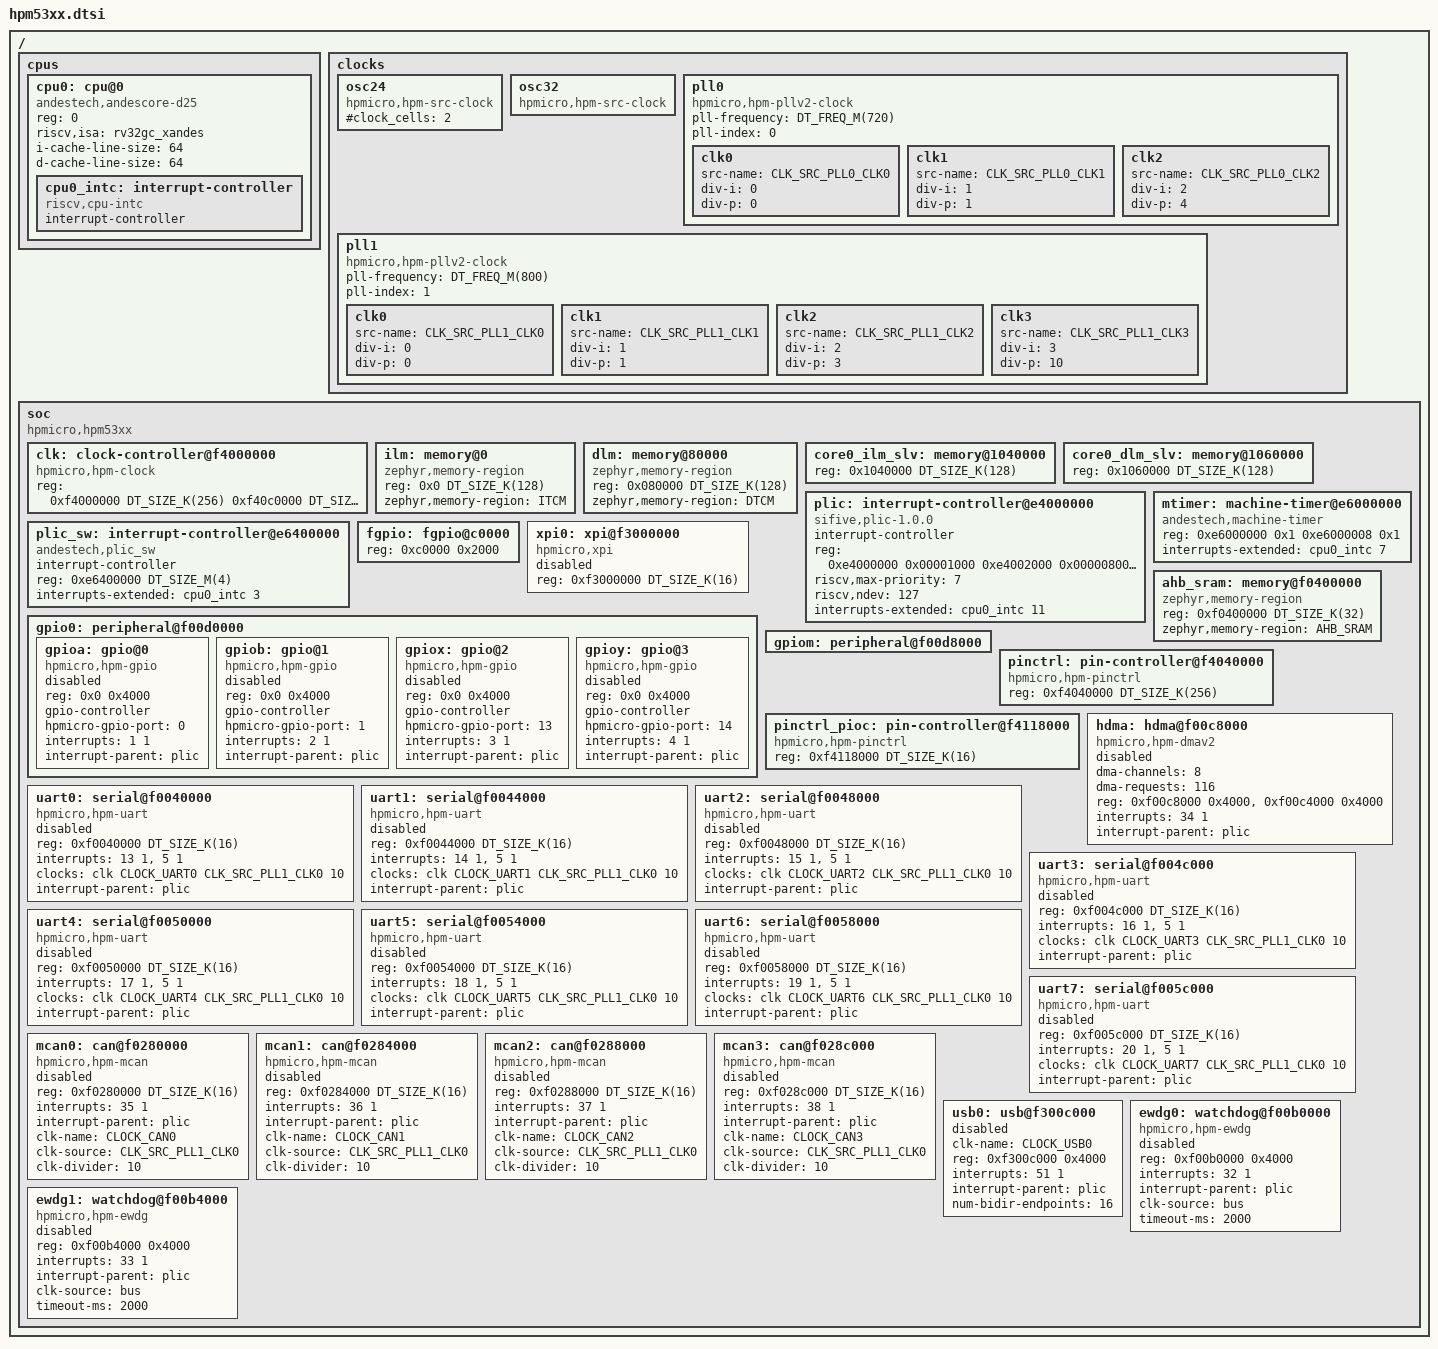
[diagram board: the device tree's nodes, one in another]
/*
 * Copyright 2024 HPMicro
 * SPDX-License-Identifier: Apache-2.0
 */

/dts-v1/;
#include <zephyr/dt-bindings/gpio/gpio.h>
#include <zephyr/dt-bindings/i2c/i2c.h>
#include <dt-bindings/clock/hpm5361-clocks.h>
#include <mem.h>
#include <freq.h>

/ {
	#address-cells = <1>;
	#size-cells = <1>;

	cpus {
		#address-cells = <1>;
		#size-cells = <0>;
		cpu0: cpu@0 {
			compatible = "andestech,andescore-d25", "riscv"; /* riscv custom */
			reg = <0>;
			status = "okay";
			riscv,isa = "rv32gc_xandes";
			i-cache-line-size = <64>;
			d-cache-line-size = <64>;

			cpu0_intc: interrupt-controller {
				compatible = "riscv,cpu-intc";
				#address-cells = <0>;
				#interrupt-cells = <1>;
				interrupt-controller;
			};
		};
	};

    clocks {
        osc24: osc24 {
            #clock_cells = <2>;
            compatible = "hpmicro,hpm-src-clock";
        };

		osc32: osc32 {
			#clock-cells = <2>;
			compatible = "hpmicro,hpm-src-clock";
		};

		pll0: pll0 {
			#clock-cells = <2>;
			compatible = "hpmicro,hpm-pllv2-clock";
			pll-frequency = <DT_FREQ_M(720)>;
			pll-index = <0>;

			clk0 {
				src-name = <CLK_SRC_PLL0_CLK0>;
				div-i = <0>;
				div-p = <0>;
			};

			clk1 {
				src-name = <CLK_SRC_PLL0_CLK1>;
				div-i = <1>;
				div-p = <1>;
			};

			clk2 {
				src-name = <CLK_SRC_PLL0_CLK2>;
				div-i = <2>;
				div-p = <4>;
			};
		};

		pll1: pll1 {
			#clock-cells = <2>;
			compatible = "hpmicro,hpm-pllv2-clock";
			pll-frequency = <DT_FREQ_M(800)>;
			pll-index = <1>;

			clk0 {
				src-name = <CLK_SRC_PLL1_CLK0>;
				div-i = <0>;
				div-p = <0>;
			};

			clk1 {
				src-name = <CLK_SRC_PLL1_CLK1>;
				div-i = <1>;
				div-p = <1>;
			};

			clk2 {
				src-name = <CLK_SRC_PLL1_CLK2>;
				div-i = <2>;
				div-p = <3>;
			};

			clk3 {
				src-name = <CLK_SRC_PLL1_CLK3>;
				div-i = <3>;
				div-p = <10>;
			};
		};
    };

    soc {
		#address-cells = <1>;
		#size-cells = <1>;
		compatible = "hpmicro,hpm53xx";
		ranges;

        clk: clock-controller@f4000000 {
            compatible = "hpmicro,hpm-clock";
            reg = <0xf4000000 DT_SIZE_K(256)
                0xf40c0000 DT_SIZE_K(256)>;
            reg-names = "sysctl", "pll";
            #clock-cells = <3>;
            status = "okay";
        };

		ilm: memory@0 {
			compatible = "zephyr,memory-region";
			reg = <0x0 DT_SIZE_K(128)>;
			zephyr,memory-region = "ITCM";
		};

		dlm: memory@80000 {
			compatible = "zephyr,memory-region";
			reg = <0x080000 DT_SIZE_K(128)>;
			zephyr,memory-region = "DTCM";
		};

		core0_ilm_slv: memory@1040000 {
			reg = <0x1040000 DT_SIZE_K(128)>;
		};

		core0_dlm_slv: memory@1060000 {
			reg = <0x1060000 DT_SIZE_K(128)>;
		};

		plic: interrupt-controller@e4000000 {
			compatible = "sifive,plic-1.0.0";
			#address-cells = <1>;
			#interrupt-cells = <2>;
			interrupt-controller;
			reg = <	0xe4000000 0x00001000
				0xe4002000 0x00000800
				0xe4200000 0x00010000 >;
			reg-names = "prio", "irq_en", "reg";
            riscv,max-priority = <7>;
            riscv,ndev = <127>;
			interrupts-extended = <&cpu0_intc 11>;
		};

		plic_sw: interrupt-controller@e6400000 {
			compatible = "andestech,plic_sw";
			#address-cells = <1>;
			#interrupt-cells = <2>;
			interrupt-controller;
			reg = <0xe6400000 DT_SIZE_M(4)>;
			interrupts-extended = <&cpu0_intc 3>;
		};

		mtimer: machine-timer@e6000000 {
			compatible = "andestech,machine-timer";
			reg = <0xe6000000 0x1
			0xe6000008 0x1>;
			interrupts-extended = <&cpu0_intc 7>;
		};

        fgpio: fgpio@c0000 {
            reg = <0xc0000 0x2000>;
        };

		xpi0: xpi@f3000000 {
			compatible = "hpmicro,xpi";
			reg = <0xf3000000 DT_SIZE_K(16)>;
			#address-cells = <1>;
			#size-cells = <1>;
			status = "disabled";
		};

		ahb_sram: memory@f0400000 {
			compatible = "zephyr,memory-region";
			reg = <0xf0400000 DT_SIZE_K(32)>;
			zephyr,memory-region = "AHB_SRAM";
		};

        gpio0: peripheral@f00d0000 {
			#address-cells = <1>;
			#size-cells = <1>;
			ranges = <0x0 0xf00d0000 DT_SIZE_K(16)>;
        };

        gpiom: peripheral@f00d8000 {
            #address-cells = <1>;
            #size-cells = <1>;
            ranges = <0x0 0xf00d8000 DT_SIZE_K(16)>;
        };

		pinctrl: pin-controller@f4040000 {
			compatible = "hpmicro,hpm-pinctrl";
			reg = <0xf4040000 DT_SIZE_K(256)>;
			status = "okay";
		};

		pinctrl_pioc: pin-controller@f4118000 {
			compatible = "hpmicro,hpm-pinctrl";
			reg = <0xf4118000 DT_SIZE_K(16)>;
			status = "okay";
		};

		hdma: hdma@f00c8000 {
			#dma-cells = <2>;
			compatible = "hpmicro,hpm-dmav2";
			dma-channels = <8>;
			dma-requests = <116>;
			reg = <0xf00c8000 0x4000>,
				<0xf00c4000 0x4000>; /* DMAMUX base */
			interrupts = <34 1>;
			interrupt-parent = <&plic>;
			status = "disabled";
		};

		uart0: serial@f0040000 {
			compatible = "hpmicro,hpm-uart";
			reg = <0xf0040000 DT_SIZE_K(16)>;
			interrupts = <13 1>, <5 1>;
			interrupt-names = "uart", "idletimer";
			clocks = <&clk CLOCK_UART0 CLK_SRC_PLL1_CLK0 10>;
			interrupt-parent = <&plic>;
			status = "disabled";
		};

		uart1: serial@f0044000 {
			compatible = "hpmicro,hpm-uart";
			reg = <0xf0044000 DT_SIZE_K(16)>;
			interrupts = <14 1>, <5 1>;
			interrupt-names = "uart", "idletimer";
			clocks = <&clk CLOCK_UART1 CLK_SRC_PLL1_CLK0 10>;
			interrupt-parent = <&plic>;
			status = "disabled";
		};

		uart2: serial@f0048000 {
			compatible = "hpmicro,hpm-uart";
			reg = <0xf0048000 DT_SIZE_K(16)>;
			interrupts = <15 1>, <5 1>;
			interrupt-names = "uart", "idletimer";
			clocks = <&clk CLOCK_UART2 CLK_SRC_PLL1_CLK0 10>;
			interrupt-parent = <&plic>;
			status = "disabled";
		};

		uart3: serial@f004c000 {
			compatible = "hpmicro,hpm-uart";
			reg = <0xf004c000 DT_SIZE_K(16)>;
			interrupts = <16 1>, <5 1>;
			interrupt-names = "uart", "idletimer";
			clocks = <&clk CLOCK_UART3 CLK_SRC_PLL1_CLK0 10>;
			interrupt-parent = <&plic>;
			status = "disabled";
		};

		uart4: serial@f0050000 {
			compatible = "hpmicro,hpm-uart";
			reg = <0xf0050000 DT_SIZE_K(16)>;
			interrupts = <17 1>, <5 1>;
			interrupt-names = "uart", "idletimer";
			clocks = <&clk CLOCK_UART4 CLK_SRC_PLL1_CLK0 10>;
			interrupt-parent = <&plic>;
			status = "disabled";
		};

		uart5: serial@f0054000 {
			compatible = "hpmicro,hpm-uart";
			reg = <0xf0054000 DT_SIZE_K(16)>;
			interrupts = <18 1>, <5 1>;
			interrupt-names = "uart", "idletimer";
			clocks = <&clk CLOCK_UART5 CLK_SRC_PLL1_CLK0 10>;
			interrupt-parent = <&plic>;
			status = "disabled";
		};

		uart6: serial@f0058000 {
			compatible = "hpmicro,hpm-uart";
			reg = <0xf0058000 DT_SIZE_K(16)>;
			interrupts = <19 1>, <5 1>;
			interrupt-names = "uart", "idletimer";
			clocks = <&clk CLOCK_UART6 CLK_SRC_PLL1_CLK0 10>;
			interrupt-parent = <&plic>;
			status = "disabled";
		};

		uart7: serial@f005c000 {
			compatible = "hpmicro,hpm-uart";
			reg = <0xf005c000 DT_SIZE_K(16)>;
			interrupts = <20 1>, <5 1>;
			interrupt-names = "uart", "idletimer";
			clocks = <&clk CLOCK_UART7 CLK_SRC_PLL1_CLK0 10>;
			interrupt-parent = <&plic>;
			status = "disabled";
		};

		mcan0: can@f0280000 {
			compatible = "hpmicro,hpm-mcan";
			reg = <0xf0280000 DT_SIZE_K(16)>;
			interrupts = <35 1>;
			interrupt-parent = <&plic>;
			clk-name = <CLOCK_CAN0>;
			clk-source = <CLK_SRC_PLL1_CLK0>;
			clk-divider = <10>;
			status = "disabled";
		};

		mcan1: can@f0284000 {
			compatible = "hpmicro,hpm-mcan";
			reg = <0xf0284000 DT_SIZE_K(16)>;
			interrupts = <36 1>;
			interrupt-parent = <&plic>;
			clk-name = <CLOCK_CAN1>;
			clk-source = <CLK_SRC_PLL1_CLK0>;
			clk-divider = <10>;
			status = "disabled";
		};

		mcan2: can@f0288000 {
			compatible = "hpmicro,hpm-mcan";
			reg = <0xf0288000 DT_SIZE_K(16)>;
			interrupts = <37 1>;
			interrupt-parent = <&plic>;
			clk-name = <CLOCK_CAN2>;
			clk-source = <CLK_SRC_PLL1_CLK0>;
			clk-divider = <10>;
			status = "disabled";
		};

		mcan3: can@f028c000 {
			compatible = "hpmicro,hpm-mcan";
			reg = <0xf028c000 DT_SIZE_K(16)>;
			interrupts = <38 1>;
			interrupt-parent = <&plic>;
			clk-name = <CLOCK_CAN3>;
			clk-source = <CLK_SRC_PLL1_CLK0>;
			clk-divider = <10>;
			status = "disabled";
		};

        usb0: usb@f300c000 {
			clk-name = <CLOCK_USB0>;
			reg = <0xf300c000 0x4000>;
			interrupts = <51 1>;
			interrupt-parent = <&plic>;
			num-bidir-endpoints = <16>;
			status = "disabled";
		};

		ewdg0: watchdog@f00b0000 {
			compatible = "hpmicro,hpm-ewdg";
			reg = <0xf00b0000 0x4000>;
			interrupts = <32 1>;
			interrupt-parent = <&plic>;
			clk-source = "bus";
			timeout-ms = <2000>;
			status = "disabled";
		};

		ewdg1: watchdog@f00b4000 {
			compatible = "hpmicro,hpm-ewdg";
			reg = <0xf00b4000 0x4000>;
			interrupts = <33 1>;
			interrupt-parent = <&plic>;
			clk-source = "bus";
			timeout-ms = <2000>;
			status = "disabled";
		};
	};
};

&gpio0 {
	gpioa: gpio@0 {
		compatible = "hpmicro,hpm-gpio";
		reg = <0x0 0x4000>;
		gpio-controller;
		#gpio-cells = <2>;
		hpmicro-gpio-port = <0>;
		interrupts = <1 1>;
		interrupt-parent = <&plic>;
		status = "disabled";
	};

	gpiob: gpio@1 {
		compatible = "hpmicro,hpm-gpio";
		reg = <0x0 0x4000>;
		gpio-controller;
		#gpio-cells = <2>;
		hpmicro-gpio-port = <1>;
		interrupts = <2 1>;
		interrupt-parent = <&plic>;
		status = "disabled";
	};

	gpiox: gpio@2 {
		compatible = "hpmicro,hpm-gpio";
		reg = <0x0 0x4000>;
		gpio-controller;
		#gpio-cells = <2>;
		hpmicro-gpio-port = <13>;
		interrupts = <3 1>;
		interrupt-parent = <&plic>;
		status = "disabled";
	};

	gpioy: gpio@3 {
		compatible = "hpmicro,hpm-gpio";
		reg = <0x0 0x4000>;
		gpio-controller;
		#gpio-cells = <2>;
		hpmicro-gpio-port = <14>;
		interrupts = <4 1>;
		interrupt-parent = <&plic>;
		status = "disabled";
	};
};
